# cyt3dl register map
Vendor: Cypress Semiconductor; Series: cyt3dl; File version: 1.0
CPU: CM7 r0p1, little endian, MPU, FPU, VTOR, 3 interrupt priority bits
Registers are 32-bit, read-write, reset 0x0 unless marked. A register's access mark holds for its fields unless they carry their own. Offsets are from the block's base; [hi:lo] are bit positions; lines under a group give offsets from that group; {n}, {i} and the like mark numbered series; 'fields as' and 'values as' point back to an identical list.

## VIDEOSS0 (part 9 of 18) — Video and Graphics Subsystem IP
Base 0x40A00000
0x80000 VIDEOIO group — Video I/O Core
  0x00 SUBIO group — Sub Interface
    0x10000 COMPENG group — Composition Engine
      0x6400 FETCHDECODE0 group — FetchDecode #0 (Display)
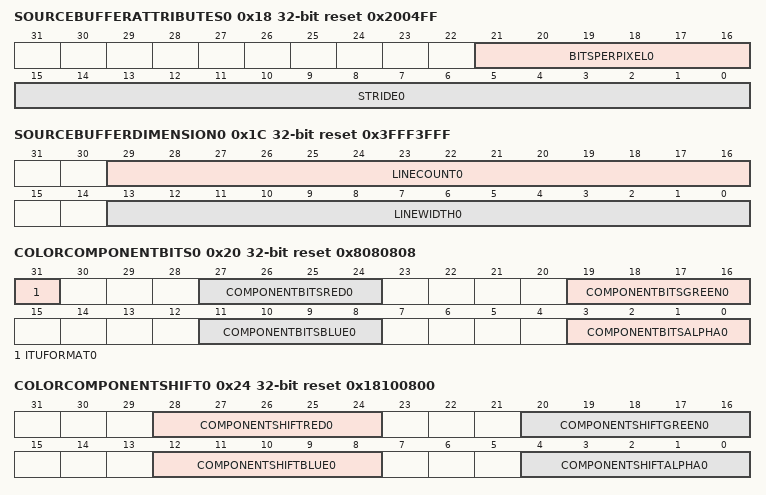
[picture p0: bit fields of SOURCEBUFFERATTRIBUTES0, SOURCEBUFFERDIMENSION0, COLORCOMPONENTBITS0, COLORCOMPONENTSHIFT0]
        0x18 SOURCEBUFFERATTRIBUTES0 reset 0x2004FF — Source buffer attributes for layer 0.
          [21:16] BITSPERPIXEL0 — Number of bits per pixel in the source buffer. Must be 1, 2, 4, 8, 16, 18, 24 or 32. [Exception] FetchEco does not support 18 and 24.
          [15:0] STRIDE0 — Source buffer stride of the layer in bytes minus one, used for address generation. For a pixel width of 32 bits Stride has to be dividable by 4 and given minus one and for a pixel width of 16 bit Stride has to be dividable by two and given minus one.
        0x1C SOURCEBUFFERDIMENSION0 reset 0x3FFF3FFF — Source buffer dimension of layer 0.
          [29:16] LINECOUNT0 — Number of lines of the source buffer of the layer minus one.
          [13:0] LINEWIDTH0 — Width of the source buffer of the layer in pixels minus one.
        0x20 COLORCOMPONENTBITS0 reset 0x8080808 — Size of color components for RGB, YUV and index formats (layer 0).
          [31] ITUFORMAT0 — When ComponentBitsRed/Green/Blue is set to 10 and this mode enabled (value 1), then input format is considered 8.2 instead of 10.0 bits (max color is 1020 instead of 1023). This is compliant to ITU 656 standard.
          [27:24] COMPONENTBITSRED0 — Red, Y (luma) and palette index.
          [19:16] COMPONENTBITSGREEN0 — Green and U (chroma).
          [11:8] COMPONENTBITSBLUE0 — Blue and V (chroma).
          [3:0] COMPONENTBITSALPHA0 — Alpha.
        0x24 COLORCOMPONENTSHIFT0 reset 0x18100800 — Bit position of color components for RGB, YUV and index formats (layer 0).
          [28:24] COMPONENTSHIFTRED0 — Red, Y (luma) and palette index.
          [20:16] COMPONENTSHIFTGREEN0 — Green and U (chroma).
          [12:8] COMPONENTSHIFTBLUE0 — Blue and V (chroma).
          [4:0] COMPONENTSHIFTALPHA0 — Alpha.
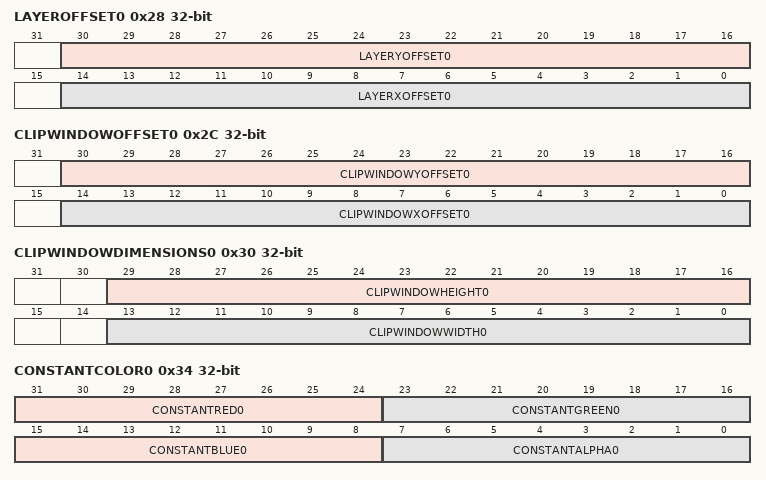
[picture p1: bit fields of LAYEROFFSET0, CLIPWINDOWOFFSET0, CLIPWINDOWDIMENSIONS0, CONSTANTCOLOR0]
        0x28 LAYEROFFSET0 — Position of layer 0 within the destination frame.
          [30:16] LAYERYOFFSET0 — Vertical offset (Y). (format is signed integer)
          [14:0] LAYERXOFFSET0 — Horizontal offset (X). (format is signed integer)
        0x2C CLIPWINDOWOFFSET0 — Clip window position for layer 0.
          [30:16] CLIPWINDOWYOFFSET0 — Vertical position (Y). (format is signed integer)
          [14:0] CLIPWINDOWXOFFSET0 — Horizontal position (X). (format is signed integer)
        0x30 CLIPWINDOWDIMENSIONS0 — Clip window size for layer 0.
          [29:16] CLIPWINDOWHEIGHT0 — Height.
          [13:0] CLIPWINDOWWIDTH0 — Width.
        0x34 CONSTANTCOLOR0 — Constant color for layer 0.
          [31:24] CONSTANTRED0 — Red and Y (luma).
          [23:16] CONSTANTGREEN0 — Green and U (chroma).
          [15:8] CONSTANTBLUE0 — Blue and V (chroma).
          [7:0] CONSTANTALPHA0 — Alpha.
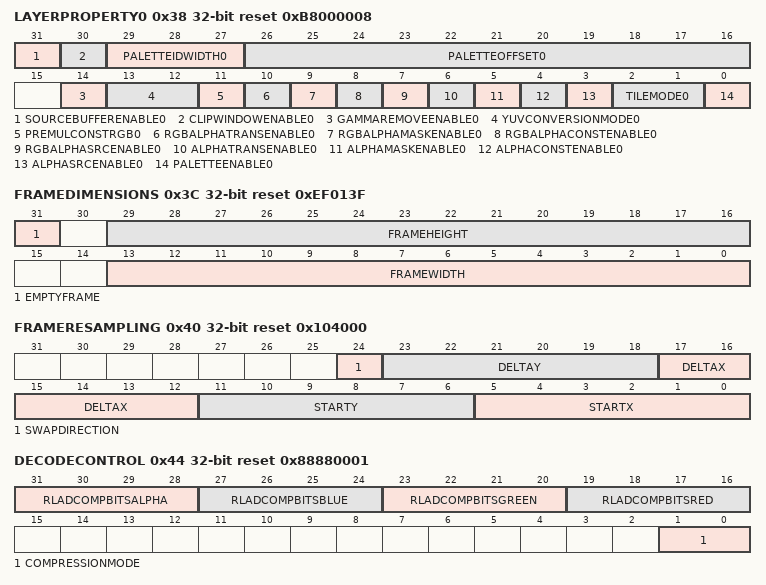
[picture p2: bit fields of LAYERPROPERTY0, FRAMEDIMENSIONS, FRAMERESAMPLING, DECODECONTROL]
        0x38 LAYERPROPERTY0 reset 0xB8000008 — Common properties of layer 0.
          [31] SOURCEBUFFERENABLE0 — Value 1 enables the source buffer for this layer. When disabled the tiling color is used only (TileMode TILE_PAD not allowed).
          [30] CLIPWINDOWENABLE0 — Value 1 enables the clip window for this layer. Pixels outside the clip window get the clip color, pixels inside the source or tiling color.
          [29:27] PALETTEIDWIDTH0 — Number minus one of least significant bits of pixel data read from the source buffer that are used as index value for color palette look-up.
          [26:16] PALETTEOFFSET0 — Palette may contain multiple areas. This offset shows to the starting position of the currently used area.
          [14] GAMMAREMOVEENABLE0 — Value 1 enables the stage to remove a gamma from RGB components.
          [13:12] YUVCONVERSIONMODE0 — Enables different kind of YUV to RGB conversions.
            0=OFF (No conversion.); 1=ITU601 (Conversion from YCbCr (YUV) to RGB according to ITU recommendation BT.601-6 (standard definition TV). Input range is 16..235 for Y and 16..240 for U/V.); 2=ITU601_FR (Conversion from YCbCr (YUV) to RGB according to ITU recommendation BT.601-6, but assuming full range YUV inputs (0..255). Most typically used for computer graphics (e.g. for JPEG encoding).); 3=ITU709 (Conversion from YCbCr (YUV) to RGB according to ITU recommendation BT.709-5 part 2 (high definition TV). Input range is 16..235 for Y and 16..240 for U/V.)
          [11] PREMULCONSTRGB0 — When enabled (value 1) the values given by ConstantRed/Green/Blue are used instead of alpha for source RGB pre-multiply. Settings RGBAlphaSrc/Const/Mask/TransEnable have no effect then.
          [10] RGBALPHATRANSENABLE0 — Value 1 enables transparent alpha (0 or 1 depending on RGB matching ConstantColor setting) for RGB pre-multiply. When disabled transparent alpha is set to 1.
          [9] RGBALPHAMASKENABLE0 — Value 1 enables mask alpha (read by another Fetch unit from a separate alpha layer) for RGB pre-multiply. When disabled mask alpha is set to 1. Alpha mask input must be enabled for this field to have effect.
          [8] RGBALPHACONSTENABLE0 — Value 1 enables constant alpha (ConstAlpha fields) for RGB pre-multiply. When disabled constant alpha is set to 1.
          [7] RGBALPHASRCENABLE0 — Value 1 enables source alpha (stored together with color component in the source buffer) for RGB pre-multiply. When disabled source alpha is set to 1.
          [6] ALPHATRANSENABLE0 — Value 1 enables transparent alpha for computing the output alpha. When disabled transparent alpha is set to 1.
          [5] ALPHAMASKENABLE0 — Value 1 enables mask alpha for computing the output alpha. When disabled mask alpha is set to 1.
          [4] ALPHACONSTENABLE0 — Value 1 enables constant alpha for computing the output alpha. When disabled constant alpha is set to 1.
          [3] ALPHASRCENABLE0 — Value 1 enables source alpha for computing the output alpha. When disabled source alpha is set to 1.
          [2:1] TILEMODE0 — Select the tile mode for pixels outside the source buffer. Clip color (0,0,0,0) takes precedence if a pixel becomes subject to both tiling and clipping.
            0=TILE_FILL_ZERO (Use zero value); 1=TILE_FILL_CONSTANT (Use constant color register value); 2=TILE_PAD (Use closest pixel from source buffer. Must not be used for DECODE or YUV422 operations or when SourceBufferEnable is 0.); 3=TILE_PAD_ZERO (Use closest pixel from source buffer but zero for alpha component. Must not be used for DECODE or YUV422 operations or when SourceBufferEnable is 0.)
          [0] PALETTEENABLE0 — Enables (value = 1) a color palette with 8 bits input and 24 bits output. Lower bits of the lookup index are read from memory (PaletteIdWidth0), upper bits are set to index of this layer. Palette output is extended by upper bits of index word read from memory (e.g. to store alpha together with index). Result is mapped to color channels according to ColorComponentBits/Shift settings.
        0x3C FRAMEDIMENSIONS reset 0xEF013F — Output frame dimension.
          [31] EMPTYFRAME — When enabled output frame is empty. FrameWidth/Height settings have no effect then. Can be used to load shadows or to generate synchronization signals only (frame/sequence complete). If enabled, InputSelect must be set to INACTIVE.
          [29:16] FRAMEHEIGHT — Frame height minus one.
          [13:0] FRAMEWIDTH — Frame width minus one.
        0x40 FRAMERESAMPLING reset 0x104000 — Resampling options for output frame.
          [24] SWAPDIRECTION — Swaps X and Y directions for re-sampling. When enabled (= 1) DeltaY is applied for horizontal and DeltaX for vertical step on destination frame.
          [23:18] DELTAY — Increment of Y coordinate for vertical step in destination frame. (format is signed fix-point 4.2)
          [17:12] DELTAX — Increment of X coordinate for horizontal step in destination frame. (format is signed fix-point 4.2)
          [11:6] STARTY — Y coordinate of first sample point relative to origin. (format is signed fix-point 4.2)
          [5:0] STARTX — X coordinate of first sample point relative to origin. (format is signed fix-point 4.2)
        0x44 DECODECONTROL reset 0x88880001 — Control options for RLAD decompression.
          [31:28] RLADCOMPBITSALPHA — Maximum for average number of bits per compressed pixel for Alpha channel. This must match the corresponding encoder setting.
          [27:24] RLADCOMPBITSBLUE — Maximum for average number of bits per compressed pixel for Blue or V (chroma) channel. This must match the corresponding encoder setting.
          [23:20] RLADCOMPBITSGREEN — Maximum for average number of bits per compressed pixel for Green or U (chroma) channel. This must match the corresponding encoder setting.
          [19:16] RLADCOMPBITSRED — Maximum for average number of bits per compressed pixel for Red or Y (luma) channel. This must match the corresponding encoder setting.
          [1:0] COMPRESSIONMODE — Algorithm that the encoder used for compression.
            0=RLAD (Run-Length Adaptive Dithering (lossy compression).); 1=RLAD_UNIFORM (Run-Length Adaptive Dithering (lossy compression; uniform package size).); 2=RLA (Run-Length Adaptive (lossless compression).); 3=RL (Standard Run-Length. In contrary to other modes is in big endian format.)
        0x48 SOURCEBUFFERLENGTH — Source buffer length for compressed data.
          [28:0] RLEWORDS — Number of 32-bit words minus one that are required to decode the run length encoded source buffer.
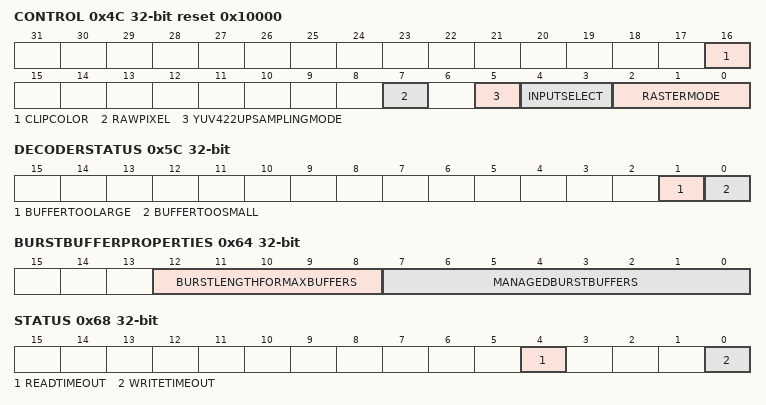
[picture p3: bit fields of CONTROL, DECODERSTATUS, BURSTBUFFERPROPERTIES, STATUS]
        0x4C CONTROL reset 0x10000 — Shared common control settings for all layers.
          [16] CLIPCOLOR — Selects which color to take for pixels that do not lie inside the clip window of any layer.
            0=NULL (Null color.); 1=LAYER (Color of layer number given by ClipLayer (or layer 0 when Fetch unit has one layer only). The color is then the layer's source or tiling color.)
          [7] RAWPIXEL — Raw pixel mode. If enabled (value = 1), the ComponentBits/Shift settings are replaced for all layers by fixed values that allow passing the pixel data read from memory unchanged to subsequent units (e.g. for reading coordinate layers). Multiply stages and transparent color are deactivated. Skip and Tile pixels are not affected by this setting.
          [5] YUV422UPSAMPLINGMODE — Selects a method for horizontal up-sampling of YUV 422/420 input data.
            0=REPLICATE (Replicate mode for interspersed samples (UV samples between Y samples).); 1=INTERPOLATE (Interpolate mode for coaligned samples (UV samples at Y sample positions).)
          [4:3] INPUTSELECT — Selects function for the frame input port.
            0=INACTIVE (Not used.); 1=COMPPACK (Used for component packing (e.g. UV or source alpha buffer).); 2=ALPHAMASK (Used for RGB and alpha pre-multiply stage (mask alpha buffer).); 3=COORDINATE (Used for arbitrary warping (coordinate buffer).)
          [2:0] RASTERMODE — Selects a method how to generate source buffer sample points.
            0=NORMAL ([IBO only, for LBO use PERSPECTIVE with corresponding Geometry] First sample at StartX/Y relative to origin. Hor/ver increments using DeltaX/Y and DeltaSwap setup.); 1=DECODE ([FetchDecode/FetchBlit only] Source buffer is an encoded bit stream. First sample at origin (0,0). Hor/ver increments = (1,0)/(0,1).); 2=ARBITRARY ([FetchBlit/Warp only] Arbitrary warping (filter is active). Coordinates are read from frame input port. InputSelect must be set to COORDINATE. ArbStartX/Y and ArbDeltaXX/XY/YX/YY must be setup.); 3=PERSPECTIVE ([FetchBlit only] Affine/Perspective warping (filter is active). First sample at PerspStartX/Y/W. Hor/ver increments using PerspDeltaXX/XY/YX/YY/WX/WY. Homogeneous coordinates. See also field Geometry to reduce coordinate amount.); 4=YUV422 ([FetchBlit/Decode only] Source buffer is packed YUV 422. First sample at origin (0,0). Hor/ver increments = (1,0)/(0,1). All correllated window widths and horizontal offsets must be even.)
        0x50 CONTROLTRIGGER wo reset not defined — Shadow load trigger.
          [0] SHDTOKGEN — Writing a 1 to this will load shadow registers into the active configuration with the next start of frame and send a shadow load token to subsequent units.
        0x54 START wo reset not defined — Frame start trigger.
          [0] START — Writing a 1 to this field will start generating one frame (for debugging purposes only).
        0x58 FETCHTYPE ro reset not defined — Fetch unit type.
          [3:0] FETCHTYPE — This field can be used to determine what kind of fetch unit this is.
            0=DECODE (Fetch unit with RL and RLAD decoder.); 1=LAYER (Fetch unit with fractional plane (8 layers).); 2=WARP (Fetch unit with arbitrary warping and fractional plane (8 layers).); 3=ECO (Fetch unit with minimum feature set for alpha, chroma and coordinate planes.); 4=PERSP (Fetch unit with affine, perspective and arbitrary warping.); 5=ROT (Fetch unit with affine and arbitrary warping.); 6=DECODEL (Fetch unit with RL and RLAD decoder, reduced feature set.); 7=LAYERL (Fetch unit with fractional plane (8 layers), reduced feature set.); 8=ROTL (Fetch unit with affine and arbitrary warping, reduced feature set.); 9=ECOL (Fetch unit with reduced minimum feature set for alpha, chroma and coordinate planes.); 10=BLIT (Fetch unit with DECODE and PERSP capabilities.)
        0x5C DECODERSTATUS — Status information of the RLAD decoder.
          [1] BUFFERTOOLARGE — The buffer size given by RLEWords is too large. A complete output frame could be decoded, but more data was read than necessary.
          [0] BUFFERTOOSMALL — The buffer size given by RLEWords is too small. No complete output frame could be decoded.
        0x60 READADDRESS0 ro — Ring buffer synchronization for layer 0.
          [31:0] READADDRESS0 — Last burst address that was read from the layer's source buffer.
        0x64 BURSTBUFFERPROPERTIES ro reset not defined
          [12:8] BURSTLENGTHFORMAXBUFFERS — Maximum Burst Length that can be used when ManagedBurstBuffers burst buffers are used.
          [7:0] MANAGEDBURSTBUFFERS — Maximum number of burst buffers that can be administrated in the AXI interface.
        0x68 STATUS — Status information.
          [4] READTIMEOUT — Timeout detected when reading from the palette entries or shadow token trigger enables in FetchLayer derivate. Write 1 to clear.
          [0] WRITETIMEOUT — Timeout detected when writing to the palette entries or shadow token trigger enables in FetchLayer derivate. Write 1 to clear.
      0x6800 GAMMACOR4 group — Video Processing Block #0 GammaCor (Capture)
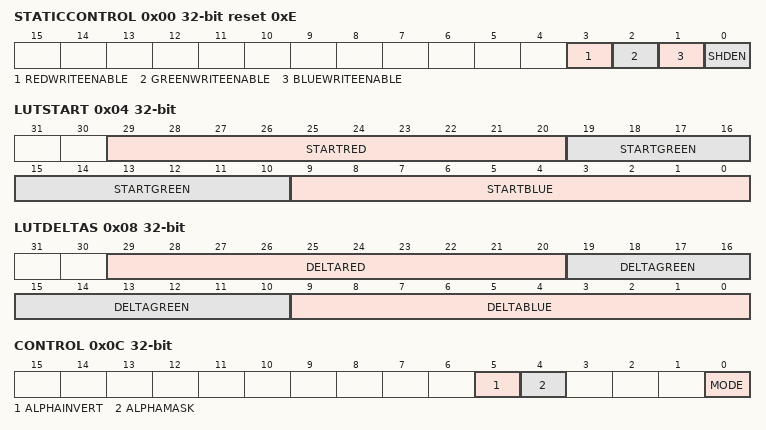
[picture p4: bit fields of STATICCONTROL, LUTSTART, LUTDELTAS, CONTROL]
        0x00 STATICCONTROL reset 0xE — Static control settings.
          [3] REDWRITEENABLE — Write enable for the red color sampling point entries.
          [2] GREENWRITEENABLE — Write enable for the green color sampling point entries.
          [1] BLUEWRITEENABLE — Write enable for the blue color sampling point entries.
          [0] SHDEN — Enables shadowing of all RWS type registers (0=write_through, 1=shadowed).
        0x04 LUTSTART wo — Start values for look-up table programming.
          [29:20] STARTRED — Start value for red or luma (Y) channel. (format is unsigned integer)
          [19:10] STARTGREEN — Start value for green or chroma (U) channel. (format is unsigned integer)
          [9:0] STARTBLUE — Start value for blue or chroma (V) channel. (format is unsigned integer)
        0x08 LUTDELTAS wo reset not defined — Delta values for look-up table programming.
          [29:20] DELTARED — Delta value for red or luma (Y) channel. (format is signed integer)
          [19:10] DELTAGREEN — Delta value for green or chroma (U) channel. (format is signed integer)
          [9:0] DELTABLUE — Delta value for blue or chroma (V) channel. (format is signed integer)
        0x0C CONTROL — Dynamic control settings.
          [5] ALPHAINVERT — Value 1 inverts the effect of the alpha mask mode when enabled (pixels with alpha value greater or equal 0.5 are by-passed).
          [4] ALPHAMASK — Value 1 enables the alpha mask mode. In this mode all pixels with an alpha value smaller than 0.5 are by-passed unchanged.
          [0] MODE — Operation mode for gamma correction unit
            0=NEUTRAL (Module in neutral mode, input data is bypassed to the output.); 1=GAMMACOR (Module in gamma correction mode.)
      0x6C00 MATRIX4 group — Video Processing Block #0 Matrix (Capture)
        0x00 STATICCONTROL — Color Matrix static control register
          [0] SHDEN — Enables shadowing of all RWS type registers (0=write_through, 1=shadowed).
        0x04 CONTROL — Color Matrix control register
          [5] ALPHAINVERT — Value 1 inverts the effect of the alpha mask mode when enabled (pixels with alpha value greater or equal 0.5 are by-passed).
          [4] ALPHAMASK — Value 1 enables the alpha mask mode. In this mode all pixels with an alpha value smaller than 0.5 are by-passed unchanged.
          [1:0] MODE — Operation mode for color matrix
            0=NEUTRAL (Module in neutral mode, input data is bypassed); 1=MATRIX (Module in matrix mode, input data is multiplied with matrix values); 2=PREMUL (Module in alpha pre-multiplication mode, input color is multiplied with input alpha); 3=RSVD (N/A)
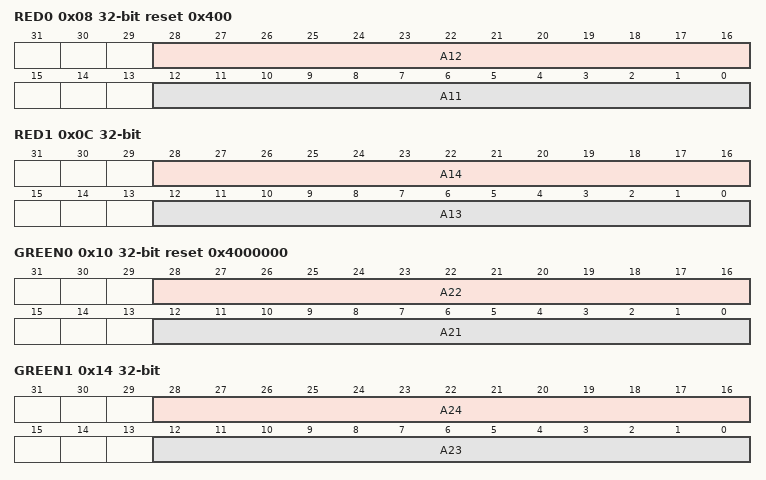
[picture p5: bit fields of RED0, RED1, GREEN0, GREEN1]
        0x08 RED0 reset 0x400 — Matrix values for calculation of the red output value.
          [28:16] A12 — Value for green input. (format is signed fix-point 3.10)
          [12:0] A11 — Value for red input. (format is signed fix-point 3.10)
        0x0C RED1 — Matrix values for calculation of the red output value.
          [28:16] A14 — Value for alpha input. (format is signed fix-point 3.10)
          [12:0] A13 — Value for blue input. (format is signed fix-point 3.10)
        0x10 GREEN0 reset 0x4000000 — Matrix values for calculation of the green output value.
          [28:16] A22 — Value for green input. (format is signed fix-point 3.10)
          [12:0] A21 — Value for red input. (format is signed fix-point 3.10)
        0x14 GREEN1 — Matrix values for calculation of the green output value.
          [28:16] A24 — Value for alpha input. (format is signed fix-point 3.10)
          [12:0] A23 — Value for blue input. (format is signed fix-point 3.10)
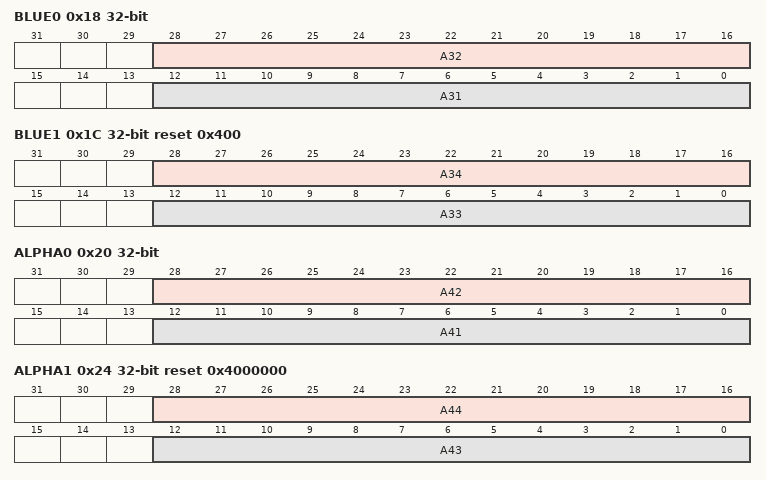
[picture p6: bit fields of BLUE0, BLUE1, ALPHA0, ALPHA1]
        0x18 BLUE0 — Matrix values for calculation of the blue output value.
          [28:16] A32 — Value for green input. (format is signed fix-point 3.10)
          [12:0] A31 — Value for red input. (format is signed fix-point 3.10)
        0x1C BLUE1 reset 0x400 — Matrix values for calculation of the blue output value.
          [28:16] A34 — Value for alpha input. (format is signed fix-point 3.10)
          [12:0] A33 — Value for blue input. (format is signed fix-point 3.10)
        0x20 ALPHA0 — Matrix values for calculation of the alpha output value.
          [28:16] A42 — Value for green input. (format is signed fix-point 3.10)
          [12:0] A41 — Value for red input. (format is signed fix-point 3.10)
        0x24 ALPHA1 reset 0x4000000 — Matrix values for calculation of the alpha output value.
          [28:16] A44 — Value for alpha input. (format is signed fix-point 3.10)
          [12:0] A43 — Value for blue input. (format is signed fix-point 3.10)
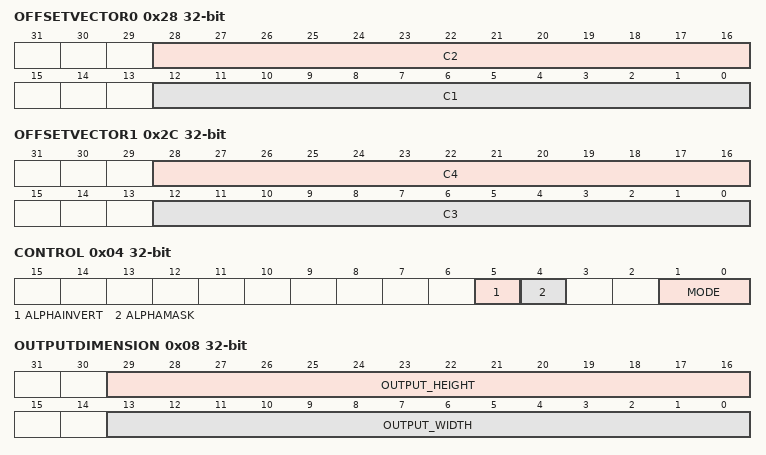
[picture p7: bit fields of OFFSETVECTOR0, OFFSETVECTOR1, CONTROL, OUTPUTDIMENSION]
        0x28 OFFSETVECTOR0 — Offset vectors for red and green output.
          [28:16] C2 — Green output offset. (format is signed integer)
          [12:0] C1 — Red output offset. (format is signed integer)
        0x2C OFFSETVECTOR1 — Offset vectors for blue and alpha output.
          [28:16] C4 — Alpha output offset. Note that the 8-bit alpha input is up-scaled to 10-bit, before the matrix and this offset is applied, and down-scaled to 8-bit for output afterwards. (format is signed integer)
          [12:0] C3 — Blue output offset. (format is signed integer)
      0x7000 GPSCALER4 group — GPscaler #4 (Capture)
        0x00 STATICCONTROL — Static control settings that must typically be setup once only.
          [0] SHDEN — If ShdEn==1 shadow registers are loaded when indicated by hardware signal ( a command signal in the data stream at frame start ). If ShdEn==0 shadow registers are loaded each frame start. (format is unsigned integer)
        0x04 CONTROL — Global operation control.
          [8] OPERATION_MODE — Selects the kind of operation to execute. (format is unsigned integer)
            0=SCALE (Scaler is active with the corresponding settings from scaler registers; filter registers are ignored.); 1=FIR (FIR-Filter is active with the corresponding settings from filter registers; scaler registers are ignored.)
          [3:0] MODE — Controls the sequence of horizontal and vertical operation for all operation modes. (format is unsigned integer)
            0=NEUTRAL (Neutral mode. Pixels are by-passed unchanged, all other settings are ignored.); 14=ACTIVE_AUTO (Automatic mode. Behaves like ACTIVE_VER_FIRST when operation_mode=SCALE and scale_mode_h=UPSCALE, like ACTIVE_HOR_FIRST otherwise.); 12=ACTIVE_HOR_FIRST (Horizontal is done before vertical operation.); 13=ACTIVE_VER_FIRST (Vertical is done before horizontal operation.); 8=ACTIVE_HOR_ONLY (Only horizontal operation is done.); 5=ACTIVE_VER_ONLY (Only vertical operation is done.)
        0x08 OUTPUTDIMENSION — Dimensions of the output frame or fame slice. This values are required for both FIR filter and scaler, since their output may have other dimension than input. The dimension of scaler's output is defined by the scale factor. The dimension of FIR filter's output depends on the tiling at the begin and the end of the slice.
          [29:16] OUTPUT_HEIGHT — Number of output lines per input frame or slice. This number is equal to the height of the output frame minus one. (format is unsigned integer)
          [13:0] OUTPUT_WIDTH — Number of output pixel per input line. This number is equal to the width of the output frame minus one. (format is unsigned integer)
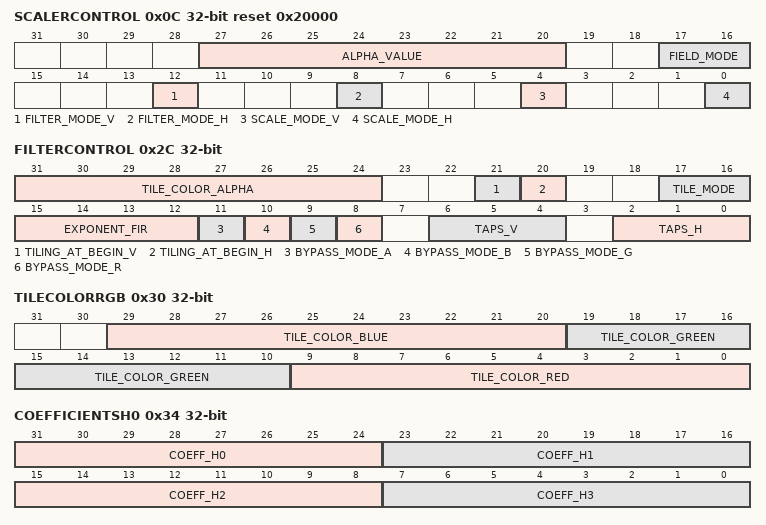
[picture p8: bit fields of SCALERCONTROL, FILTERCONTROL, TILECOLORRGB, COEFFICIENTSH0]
        0x0C SCALERCONTROL reset 0x20000 — Scaler operation control.
          [27:20] ALPHA_VALUE — When 'mode' field is not 'NEUTRAL', then input alpha values are ignore and output alpha set to this constant value for all pixels. This restriction applies to GPScalerL derivative only. (format is unsigned integer)
          [17:16] FIELD_MODE — Controls generation of output field polarity for vertical scaling. (format is unsigned integer)
            0=ALWAYS0 (Constant 0 indicates frame or top field.); 1=ALWAYS1 (Constant 1 indicates bottom field.); 2=INPUT (Output field polarity is taken from input field polarity.); 3=TOGGLE (Output field polarity toggles, starting with 0 after reset.)
          [12] FILTER_MODE_V — Selects sampling algorithm for vertical scaling. (format is unsigned integer)
            0=NEAREST (Nearest filter (point-sampling)); 1=LINEAR (Box filter (linear))
          [8] FILTER_MODE_H — Selects sampling algorithm for horizontal scaling. (format is unsigned integer)
            values as FILTER_MODE_V
          [4] SCALE_MODE_V — Scale mode for vertical scaling. (format is unsigned integer)
            0=DOWNSCALE (Down-scaling (output height less or equal input height).); 1=UPSCALE (Up-scaling (output height greater or equal input height))
          [0] SCALE_MODE_H — Scale mode for horizontal scaling. (format is unsigned integer)
            0=DOWNSCALE (Down-scaling (output width is less or equal input width).); 1=UPSCALE (Up-scaling (output width greater or equal input width))
        0x10 SCALERSETUPH0 reset 0x80000 — Phase interpolator setup.
          [19:0] SCALE_FACTOR_H — Scale factor has to be greater than 0.0 and less than or equal to 1.0. If scale_mode is UPSCALE then the inverse scale factor has to be programmed. (format is unsigned fix-point 1.19)
        0x14 SCALERSETUPH1 — Phase interpolator setup.
          [20:0] PHASE_OFFSET_H — Phase offset has to be larger than -2 and smaller than +2. Depending on scale_mode this value is relative to input (UPSCALE) or output pixel (DOWNSCALE). A negative value shifts the image to the right, a positive one to the left. (format is signed fix-point 2.19)
        0x18 SCALERSETUPV0 reset 0x80000 — Phase interpolator setup.
          [19:0] SCALE_FACTOR_V — Scale factor is greater than 0.0 and less than or equal to 1.0. If scale_mode is UPSCALE then the inverse scale factor have to be programmed. (format is unsigned fix-point 1.19)
        0x1C SCALERSETUPV1 — Phase interpolator setup, selected if input and output field polarity is 0.
          [20:0] PHASE_OFFSET_V — Phase offset has to be larger than -2 and smaller than +2. Depending on scale_mode this value is relative to input (UPSCALE) or output pixel (DOWNSCALE). A negative value shifts the image to the bottom, a positive one to the top. (format is signed fix-point 2.19)
        0x20 SCALERSETUPV2 — Phase interpolator setup, selected if input field polarity is 1 and output field polarity is 0.
          [20:0] PHASE_OFFSET_V1 — Phase offset has to be larger than -2 and smaller than +2. Depending on scale_mode this value is relative to input (UPSCALE) or output pixel (DOWNSCALE). A negative value shifts the image to the bottom, a positive one to the top. (format is signed fix-point 2.19)
        0x24 SCALERSETUPV3 — Phase interpolator setup, selected if input field polarity is 0 and output field polarity is 1.
          [20:0] PHASE_OFFSET_V2 — Phase offset has to be larger than -2 and smaller than +2. Depending on scale_mode this value is relative to input (UPSCALE) or output pixel (DOWNSCALE). A negative value shifts the image to the bottom, a positive one to the top. (format is signed fix-point 2.19)
        0x28 SCALERSETUPV4 — Phase interpolator setup, selected if input and output field polarity is 1.
          [20:0] PHASE_OFFSET_V3 — Phase offset has to be larger than -2 and smaller than +2. Depending on scale_mode this value is relative to input (UPSCALE) or output pixel (DOWNSCALE). A negative value shifts the image to the bottom, a positive one to the top. (format is signed fix-point 2.19)
        0x2C FILTERCONTROL — Filter operation control.
          [31:24] TILE_COLOR_ALPHA — Sets the alpha value for pixels outside of the slice. (format is unsigned integer)
          [21] TILING_AT_BEGIN_V — If set to true, this bit enables tiling at the begin of the slice for vertical direction. Tiling at the end occurs automatically by setting the corresponding output size. (format is unsigned integer)
          [20] TILING_AT_BEGIN_H — If set to true, this bit enables tiling at the begin of the slice for horizontal direction. Tiling at the end occurs automatically by setting the corresponding output size. (format is unsigned integer)
          [17:16] TILE_MODE — Selects the tile mode for pixels outside the source frame. In order to enable tiling tiling_at_begin_h or tiling_at_begin_v and the corresponding output frame dimension have to be set. (format is unsigned integer)
            0=TILE_FILL_ZERO (Use zero value.); 1=TILE_FILL_CONSTANT (Use constant color value from the field tile_color.); 2=TILE_PAD (Use closest pixel from source frame.); 3=TILE_PAD_ZERO (Use closest pixel from source buffer but zero for alpha component.)
          [15:12] EXPONENT_FIR — FIR product sum is divided by 2**FIR_exponent and rounded. (format is unsigned integer)
          [11] BYPASS_MODE_A — Bypass configuration for alpha components of every pixel. (format is unsigned integer)
            0=NEUTRAL (Alpha is filtered.); 1=ACTIVE (Alpha is not filtered, but is written to the line buffer.)
          [10] BYPASS_MODE_B — Bypass configuration for blue color components of every pixel. (format is unsigned integer)
            0=NEUTRAL (Blue color is filtered.); 1=ACTIVE (Blue color is not filtered, but is written to the line buffer.)
          [9] BYPASS_MODE_G — Bypass configuration for green color components of every pixel. (format is unsigned integer)
            0=NEUTRAL (Green color is filtered.); 1=ACTIVE (Green color is not filtered, but is written to the line buffer.)
          [8] BYPASS_MODE_R — Bypass configuration for red color components of every pixel. (format is unsigned integer)
            0=NEUTRAL (Red color is filtered.); 1=ACTIVE (Red color is not filtered, but is written to the line buffer.)
          [6:4] TAPS_V — Defines the vertical size of the FIR filter between 1 and 15 with increment of 2. Only odd filter width is supported. To program this field following formula has to be used: (filter height - 1)/2 (format is unsigned integer)
          [2:0] TAPS_H — Defines the horizontal size of the FIR filter between 1 and 15 with increment of 2. Only odd filter width is supported. To program this field following formula has to be used: (filter width - 1)/2 (format is unsigned integer)
        0x30 TILECOLORRGB — Color for outside of the slice.
          [29:20] TILE_COLOR_BLUE — Sets the blue color value for pixels outside of the slice. (format is unsigned integer)
          [19:10] TILE_COLOR_GREEN — Sets the green color value for pixels outside of the slice. (format is unsigned integer)
          [9:0] TILE_COLOR_RED — Sets the red color value for pixels outside of the slice. (format is unsigned integer)
        0x34 COEFFICIENTSH0 — Horizontal coefficients for filter_mode FIR.
          [31-8n:24-8n] COEFF_H{n} (n=0..3) — Horizontal coefficient {n}. (format is signed integer)
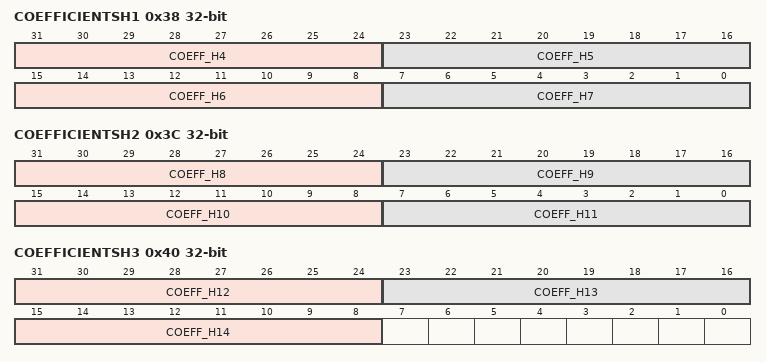
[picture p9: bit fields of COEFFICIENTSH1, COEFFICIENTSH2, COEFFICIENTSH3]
        0x38 COEFFICIENTSH1 — Horizontal coefficients for filter_mode FIR.
          [63-8n:56-8n] COEFF_H{n} (n=4..7) — Horizontal coefficient {n}. (format is signed integer)
        0x3C COEFFICIENTSH2 — Horizontal coefficients for filter_mode FIR.
          [95-8n:88-8n] COEFF_H{n} (n=8..11) — Horizontal coefficient {n}. (format is signed integer)
        0x40 COEFFICIENTSH3 — Horizontal coefficients for filter_mode FIR.
          [31:24] COEFF_H12 — Horizontal coefficient 12. (format is signed integer)
          [23:16] COEFF_H13 — Horizontal coefficient 13. (format is signed integer)
          [15:8] COEFF_H14 — Horizontal coefficient 14. The rightmost coefficient regardless of the filter width. In contrast to the coeff_h0 this coefficient has to be always programmed. (format is signed integer)

## Notices in the file
Copyright 2016-2019, Cypress Semiconductor Corporation.  All rights reserved.
You may use this file only in accordance with the license, terms, conditions,
disclaimers, and limitations in the end user license agreement accompanying
the software package with which this file was provided.
